AUTOSAR XML (schema 4-0-3)
package /ComponentTypes
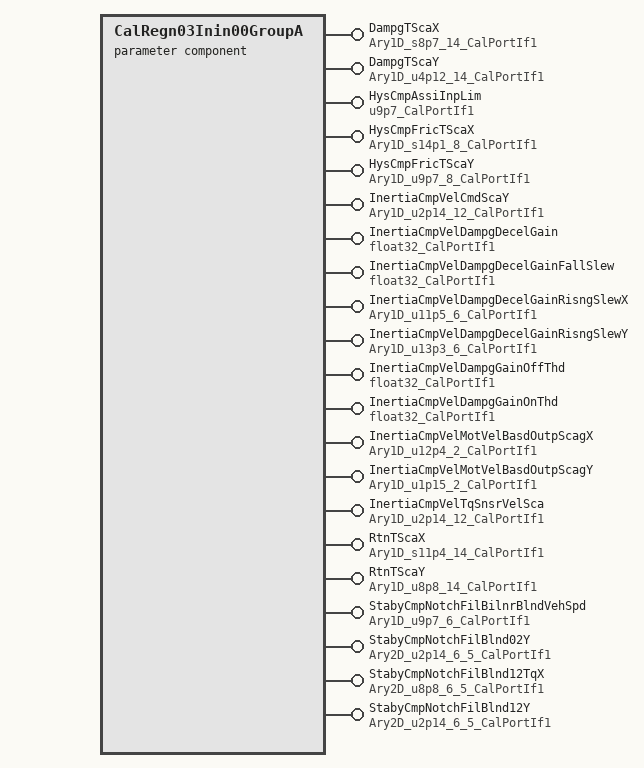
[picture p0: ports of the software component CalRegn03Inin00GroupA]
  parameter sw component type CalRegn03Inin00GroupA
    21 x provide port:
      DampgTScaX: parameter-provide-com-spec{init-value=[-5120, -4480, -3840, -2560, -1280, 0, 1280, 2560, 3840, 5120, 6400, 7680, 8960, 11520], parameter=Ary1D}, provided-interface=Ary1D_s8p7_14_CalPortIf1
      DampgTScaY: parameter-provide-com-spec{init-value=14 x 4096, parameter=Ary1D}, provided-interface=Ary1D_u4p12_14_CalPortIf1
      HysCmpAssiInpLim: parameter-provide-com-spec{init-value=45056, parameter=Val}, provided-interface=u9p7_CalPortIf1
      HysCmpFricTScaX: parameter-provide-com-spec{init-value=[-80, -60, -40, -20, 0, 50, 100, 160], parameter=Ary1D}, provided-interface=Ary1D_s14p1_8_CalPortIf1
      HysCmpFricTScaY: parameter-provide-com-spec{init-value=8 x 128, parameter=Ary1D}, provided-interface=Ary1D_u9p7_8_CalPortIf1
      InertiaCmpVelCmdScaY: parameter-provide-com-spec{init-value=12 x 384, parameter=Ary1D}, provided-interface=Ary1D_u2p14_12_CalPortIf1
      InertiaCmpVelDampgDecelGain: parameter-provide-com-spec{init-value=1, parameter=Val}, provided-interface=float32_CalPortIf1
      InertiaCmpVelDampgDecelGainFallSlew: parameter-provide-com-spec{init-value=-4500, parameter=Val}, provided-interface=float32_CalPortIf1
      InertiaCmpVelDampgDecelGainRisngSlewX: parameter-provide-com-spec{init-value=[0, 640, 1088, 1120, 1152, 1184], parameter=Ary1D}, provided-interface=Ary1D_u11p5_6_CalPortIf1
      InertiaCmpVelDampgDecelGainRisngSlewY: parameter-provide-com-spec{init-value=6 x 36000, parameter=Ary1D}, provided-interface=Ary1D_u13p3_6_CalPortIf1
      InertiaCmpVelDampgGainOffThd: parameter-provide-com-spec{init-value=1, parameter=Val}, provided-interface=float32_CalPortIf1
      InertiaCmpVelDampgGainOnThd: parameter-provide-com-spec{init-value=10, parameter=Val}, provided-interface=float32_CalPortIf1
      InertiaCmpVelMotVelBasdOutpScagX: parameter-provide-com-spec{init-value=[1005, 1100], parameter=Ary1D}, provided-interface=Ary1D_u12p4_2_CalPortIf1
      InertiaCmpVelMotVelBasdOutpScagY: parameter-provide-com-spec{init-value=[32768, 32768], parameter=Ary1D}, provided-interface=Ary1D_u1p15_2_CalPortIf1
      InertiaCmpVelTqSnsrVelSca: parameter-provide-com-spec{init-value=12 x 0, parameter=Ary1D}, provided-interface=Ary1D_u2p14_12_CalPortIf1
      RtnTScaX: parameter-provide-com-spec{init-value=[-640, -560, -480, -320, -160, 0, 160, 320, 480, 640, 800, 960, 1120, 1440], parameter=Ary1D}, provided-interface=Ary1D_s11p4_14_CalPortIf1
      RtnTScaY: parameter-provide-com-spec{init-value=14 x 256, parameter=Ary1D}, provided-interface=Ary1D_u8p8_14_CalPortIf1
      StabyCmpNotchFilBilnrBlndVehSpd: parameter-provide-com-spec{init-value=[0, 1280, 3840, 5760, 7680, 10240], parameter=Ary1D}, provided-interface=Ary1D_u9p7_6_CalPortIf1
      StabyCmpNotchFilBlnd02Y: parameter-provide-com-spec{init-value=6 x 5 x 16384, parameter=Ary2D}, provided-interface=Ary2D_u2p14_6_5_CalPortIf1
      StabyCmpNotchFilBlnd12TqX: parameter-provide-com-spec{init-value=[5 x 0, 5 x 512, 5 x 768, 5 x 1024, 5 x 1536, 5 x 2048], parameter=Ary2D}, provided-interface=Ary2D_u8p8_6_5_CalPortIf1
      StabyCmpNotchFilBlnd12Y: parameter-provide-com-spec{init-value=6 x 5 x 0, parameter=Ary2D}, provided-interface=Ary2D_u2p14_6_5_CalPortIf1
